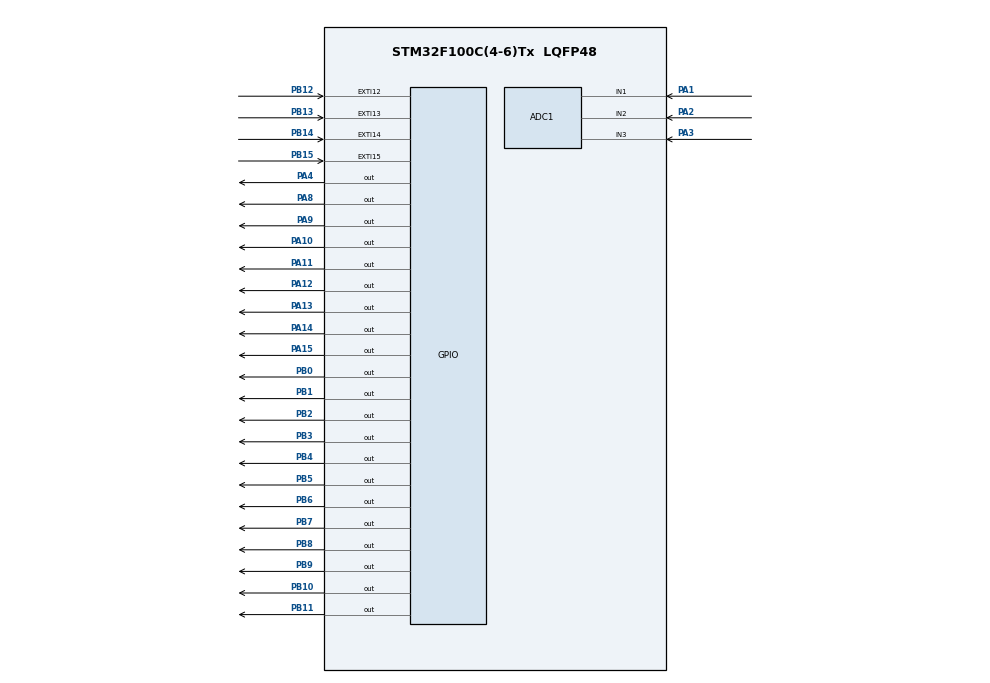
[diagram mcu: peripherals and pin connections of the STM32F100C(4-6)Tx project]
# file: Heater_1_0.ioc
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ADC1.Channel-0\#ChannelRegularConversion=ADC_CHANNEL_1
ADC1.NbrOfConversionFlag=1
ADC1.Rank-0\#ChannelRegularConversion=1
ADC1.SamplingTime-0\#ChannelRegularConversion=ADC_SAMPLETIME_1CYCLE_5
ADC1.master=1
Mcu.Family=STM32F1
Mcu.Name=STM32F100C(4-6)Tx
Mcu.Package=LQFP48
NVIC.ADC1_IRQn=true\:0\:0\:false\:false\:true
NVIC.EXTI15_10_IRQn=true\:0\:0\:false\:false\:true
NVIC.PriorityGroup=NVIC_PRIORITYGROUP_4
NVIC.RTC_Alarm_IRQn=true\:0\:0\:false\:false\:true
NVIC.RTC_IRQn=true\:0\:0\:false\:false\:true
PA1.Signal=ADCx_IN1
PA10.Signal=GPIO_Output
PA11.Signal=GPIO_Output
PA12.Signal=GPIO_Output
PA13.Signal=GPIO_Output
PA14.Signal=GPIO_Output
PA15.Signal=GPIO_Output
PA2.Signal=ADCx_IN2
PA3.Signal=ADCx_IN3
PA4.Signal=GPIO_Output
PA8.Signal=GPIO_Output
PA9.Signal=GPIO_Output
PB0.GPIO_ModeDefaultOutputPP=GPIO_MODE_OUTPUT_OD
PB0.GPIO_Speed=GPIO_SPEED_FREQ_LOW
PB0.PinState=GPIO_PIN_RESET
PB0.Signal=GPIO_Output
PB1.GPIO_ModeDefaultOutputPP=GPIO_MODE_OUTPUT_OD
PB1.GPIO_Speed=GPIO_SPEED_FREQ_LOW
PB1.PinState=GPIO_PIN_RESET
PB1.Signal=GPIO_Output
PB10.GPIO_ModeDefaultOutputPP=GPIO_MODE_OUTPUT_PP
PB10.GPIO_Speed=GPIO_SPEED_FREQ_HIGH
PB10.PinState=GPIO_PIN_RESET
PB10.Signal=GPIO_Output
PB11.GPIO_ModeDefaultOutputPP=GPIO_MODE_OUTPUT_PP
PB11.GPIO_Speed=GPIO_SPEED_FREQ_HIGH
PB11.PinState=GPIO_PIN_RESET
PB11.Signal=GPIO_Output
PB12.GPIO_ModeDefaultEXTI=GPIO_MODE_IT_FALLING
PB12.GPIO_PuPd=GPIO_PULLUP
PB12.Signal=GPXTI12
PB13.GPIO_ModeDefaultEXTI=GPIO_MODE_IT_FALLING
PB13.GPIO_PuPd=GPIO_PULLUP
PB13.Signal=GPXTI13
PB14.GPIO_ModeDefaultEXTI=GPIO_MODE_IT_FALLING
PB14.GPIO_PuPd=GPIO_PULLUP
PB14.Signal=GPXTI14
PB15.GPIO_ModeDefaultEXTI=GPIO_MODE_IT_FALLING
PB15.GPIO_PuPd=GPIO_PULLUP
PB15.Signal=GPXTI15
PB2.GPIO_ModeDefaultOutputPP=GPIO_MODE_OUTPUT_OD
PB2.GPIO_Speed=GPIO_SPEED_FREQ_LOW
PB2.PinState=GPIO_PIN_RESET
PB2.Signal=GPIO_Output
PB3.Signal=GPIO_Output
PB4.Signal=GPIO_Output
PB5.Signal=GPIO_Output
PB6.Signal=GPIO_Output
PB7.Signal=GPIO_Output
PB8.GPIO_ModeDefaultOutputPP=GPIO_MODE_OUTPUT_PP
PB8.GPIO_Speed=GPIO_SPEED_FREQ_HIGH
PB8.PinState=GPIO_PIN_RESET
PB8.Signal=GPIO_Output
PB9.GPIO_ModeDefaultOutputPP=GPIO_MODE_OUTPUT_PP
PB9.GPIO_Speed=GPIO_SPEED_FREQ_HIGH
PB9.PinState=GPIO_PIN_RESET
PB9.Signal=GPIO_Output
PD0-OSC_IN.Mode=HSE-External-Oscillator
PD0-OSC_IN.Signal=RCC_OSC_IN
PD1-OSC_OUT.Mode=HSE-External-Oscillator
PD1-OSC_OUT.Signal=RCC_OSC_OUT
ProjectManager.HeapSize=0x200
ProjectManager.StackSize=0x400
ProjectManager.TargetToolchain=MDK-ARM V5
RCC.AHBFreq_Value=24000000
RCC.APB1Freq_Value=24000000
RCC.APB1TimFreq_Value=24000000
RCC.APB2Freq_Value=24000000
RCC.APB2TimFreq_Value=24000000
RCC.HCLKFreq_Value=24000000
RCC.HSE_VALUE=24000000
RCC.PLLSource=RCC_PLLSOURCE_HSE
RCC.RTCClockSelection=RCC_RTCCLKSOURCE_HSE_DIV128
RCC.SYSCLKFreq_VALUE=24000000
RCC.SYSCLKSource=RCC_SYSCLKSOURCE_HSE
RTC.Format=RTC_FORMAT_BCD
SH.ADCx_IN1.0=ADC1_IN1,IN1
SH.ADCx_IN2.0=ADC1_IN2,IN2
SH.ADCx_IN3.0=ADC1_IN3,IN3
VP_ADC1_TempSens_Input.Mode=IN-TempSens
VP_RTC_No_RTC_Output.Mode=RTC_OUT_NO
VP_SYS_VS_ND.Mode=No_Debug
board=Heater_1_0

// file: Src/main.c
#include "stm32f1xx_hal.h"

/* USER CODE BEGIN Includes */

#include "rcc.h"
#include "gpio.h"
#include "display.h"
#include "ugui.h"
#include "interface.h"
#include "regulator.h"

/* USER CODE END Includes */

/* USER CODE BEGIN PV */

/* Private variables ---------------------------------------------------------*/
/* USER CODE END PV */

/* USER CODE BEGIN PFP */
/* Private function prototypes -----------------------------------------------*/
/* USER CODE END PFP */

int main(void)
{
  /* USER CODE BEGIN 1 */
	//char screen[SCREEN_HEIGHT*SCREEN_WIDTH]={0};
	//screen_ptr = screen;
  /* USER CODE END 1 */
  /* MCU Configuration----------------------------------------------------------*/
  /* Reset of all peripherals, Initializes the Flash interface and the Systick. */
  HAL_Init();
  /* Configure the system clock */
  SystemClock_Config();
  /* Initialize all configured peripherals */
  MX_RTC_Init();
	MX_GPIO_Init();
  MX_ADC1_Init();

  /* USER CODE BEGIN 2 */

Fan(1);
Ignition(0);
Valve(0);
Regulator_Init();
Display_Init();
HAL_Delay(500);
Ignition(1);

  /* USER CODE END 2 */

  /* Infinite loop */
  while (1)
  {
		Average_temp();
		if(Minute_interval_1()) Set_pwr();
		if(Opt_sensor()<2000){
			Ignition(1);

		}
		else{
			Ignition(0);

		}
		//Gauge_display();
		menu();
		//if(Second_interval_1())Log_Temp();

		/* USER CODE BEGIN 3 */
Lcd_print_screen();
  }
  /* USER CODE END 3 */

}
